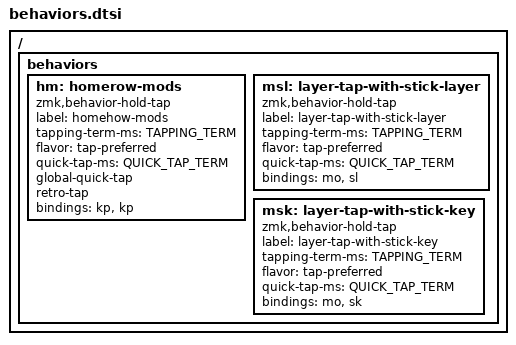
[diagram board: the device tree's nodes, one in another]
/*
*
* Copyright (c) 2022 Rafael Romão
* SPDX-License-Identifier: MIT
*
*/

/ {
    behaviors {
        hm: homerow-mods {
            compatible = "zmk,behavior-hold-tap";
            label = "homehow-mods";
            #binding-cells = <2>;
            tapping-term-ms = <TAPPING_TERM>;
            flavor = "tap-preferred";
            quick-tap-ms = <QUICK_TAP_TERM>;
            global-quick-tap;
            retro-tap;
            bindings = <&kp>, <&kp>;
        };
        msl: layer-tap-with-stick-layer {
            compatible = "zmk,behavior-hold-tap";
            label = "layer-tap-with-stick-layer";
            #binding-cells = <2>;
            tapping-term-ms = <TAPPING_TERM>;
            flavor = "tap-preferred";
            quick-tap-ms = <QUICK_TAP_TERM>;
            bindings = <&mo>, <&sl>;
        };
        msk: layer-tap-with-stick-key {
            compatible = "zmk,behavior-hold-tap";
            label = "layer-tap-with-stick-key";
            #binding-cells = <2>;
            tapping-term-ms = <TAPPING_TERM>;
            flavor = "tap-preferred";
            quick-tap-ms = <QUICK_TAP_TERM>;
            bindings = <&mo>, <&sk>;
        };
    };
};
